# ESP32-C61 register map
Vendor: ESPRESSIF SYSTEMS (SHANGHAI) CO., LTD.; Series: ESP32 C-Series; File version: 1
CPU: RV32IMAC r0p0, little endian, no MPU, no FPU, 0 interrupt priority bits
Address unit: 32 bits
Registers are 32-bit, read-write, reset 0x0 unless marked. A register's access mark holds for its fields unless they carry their own. Offsets are from the block's base; [hi:lo] are bit positions; {n}, {i} and the like mark numbered series; 'fields as' and 'values as' point back to an identical list.

## SLC — SDIO SLC
Base 0x60017000
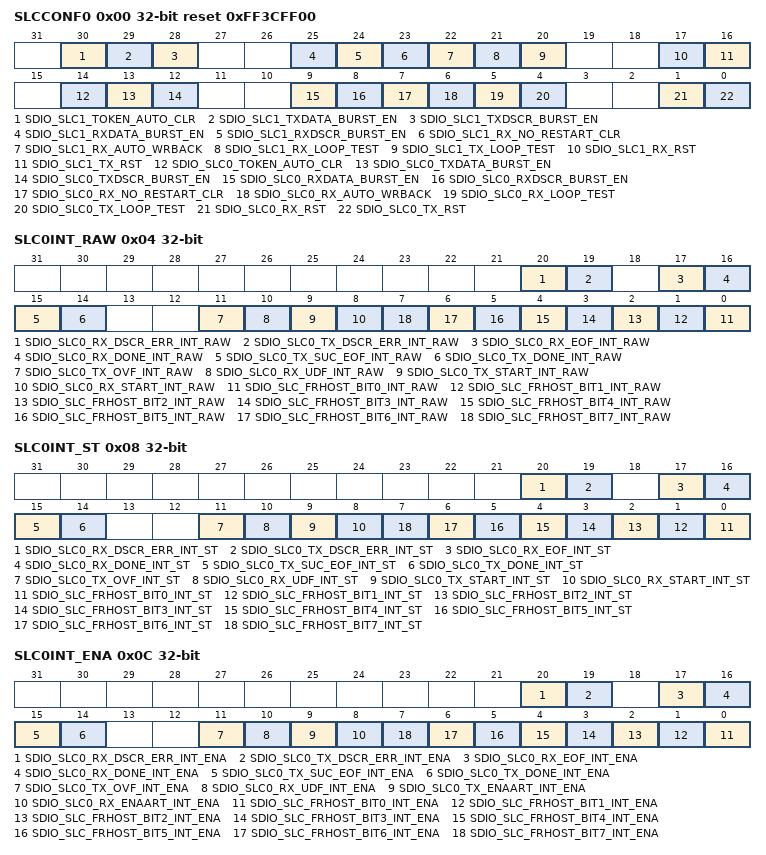
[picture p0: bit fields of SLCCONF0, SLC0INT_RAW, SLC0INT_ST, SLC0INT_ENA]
0x00 SLCCONF0 reset 0xFF3CFF00 — DMA configuration
  [30] SDIO_SLC1_TOKEN_AUTO_CLR — Please initialize to 0, and do not modify it.
  [29] SDIO_SLC1_TXDATA_BURST_EN — Configures whether SCL1 can use AHB burst operation when send data to memory.
  [28] SDIO_SLC1_TXDSCR_BURST_EN — Configures whether SCL1 can use AHB burst operation when read the TX linked list from memory.
  [25] SDIO_SLC1_RXDATA_BURST_EN — Configures whether SCL1 can use AHB burst operation when reading data from memory.
  [24] SDIO_SLC1_RXDSCR_BURST_EN — Configures whether SCL1 can use AHB burst operation when read the RX linked list from memory.
  [23] SDIO_SLC1_RX_NO_RESTART_CLR — Please initialize to 1, and do not modify it.
  [22] SDIO_SLC1_RX_AUTO_WRBACK — Configures whether SCL1 changes the owner bit of the RX linked list.
  [21] SDIO_SLC1_RX_LOOP_TEST — Configures whether SCL1 loops around when the slave buffer finishes sending packets to the host.
  [20] SDIO_SLC1_TX_LOOP_TEST — Configures whether SCL1 loops around when the slave buffer finishes receiving packets from the host.
  [17] SDIO_SLC1_RX_RST — Configures whether to reset RX FSM in SLC1.
  [16] SDIO_SLC1_TX_RST — Configures whether to reset TX FSM in SLC1.
  [14] SDIO_SLC0_TOKEN_AUTO_CLR — Please initialize to 0, and do not modify it.
  [13] SDIO_SLC0_TXDATA_BURST_EN — Configures whether SCL0 can use AHB burst operation when send data to memory.
  [12] SDIO_SLC0_TXDSCR_BURST_EN — Configures whether SCL0 can use AHB burst operation when read the TX linked list from memory.
  [9] SDIO_SLC0_RXDATA_BURST_EN — Configures whether SCL0 can use AHB burst operation when read data from memory.
  [8] SDIO_SLC0_RXDSCR_BURST_EN — Configures whether SCL0 can use AHB burst operation when reading the RX linked list from memory.
  [7] SDIO_SLC0_RX_NO_RESTART_CLR — Please initialize to 1, and do not modify it.
  [6] SDIO_SLC0_RX_AUTO_WRBACK — Configures whether SCL0 changes the owner bit of RX linked list.
  [5] SDIO_SLC0_RX_LOOP_TEST — Configures whether SCL0 loops around when the slave buffer finishes sending packets to the host.
  [4] SDIO_SLC0_TX_LOOP_TEST — Configures whether SCL0 loops around when the slave buffer finishes receiving packets from the host.
  [1] SDIO_SLC0_RX_RST — Configures whether to reset RX (slave to host) FSM in SCL0.
  [0] SDIO_SLC0_TX_RST — Configures whether to reset TX (host to slave) FSM (finite state machine) in SLC0.
0x04 SLC0INT_RAW — SLC0 to slave raw interrupt status
  [20] SDIO_SLC0_RX_DSCR_ERR_INT_RAW — The raw interrupt status of SLC0_RX_DSCR_ERR_INT.
  [19] SDIO_SLC0_TX_DSCR_ERR_INT_RAW — The raw interrupt status of SLC0_TX_DSCR_ERR_INT.
  [17] SDIO_SLC0_RX_EOF_INT_RAW — The raw interrupt status of SLC0_RX_EOF_INT.
  [16] SDIO_SLC0_RX_DONE_INT_RAW — The raw interrupt status of SLC0_RX_DONE_INT.
  [15] SDIO_SLC0_TX_SUC_EOF_INT_RAW — The raw interrupt status of SLC0_TX_SUC_EOF_INT.
  [14] SDIO_SLC0_TX_DONE_INT_RAW — The raw interrupt status of SLC0_TX_DONE_INT.
  [11] SDIO_SLC0_TX_OVF_INT_RAW — The raw interrupt status of SLC0_TX_OVF_INT.
  [10] SDIO_SLC0_RX_UDF_INT_RAW — The raw interrupt status of SLC0_RX_UDF_INT.
  [9] SDIO_SLC0_TX_START_INT_RAW — The raw interrupt status of SLC0_TX_START_INT.
  [8] SDIO_SLC0_RX_START_INT_RAW — The raw interrupt status of SLC0_RX_START_INT.
  [n] SDIO_SLC_FRHOST_BIT{n}_INT_RAW (n=0..7) — The raw interrupt status of SLC_FRHOST_BITn_INT (n: 0-7).
0x08 SLC0INT_ST ro — SLC0 to slave masked interrupt status
  [20] SDIO_SLC0_RX_DSCR_ERR_INT_ST — The masked interrupt status of SLC0_RX_DSCR_ERR_INT.
  [19] SDIO_SLC0_TX_DSCR_ERR_INT_ST — The masked interrupt status of SLC0_TX_DSCR_ERR_INT.
  [17] SDIO_SLC0_RX_EOF_INT_ST — The masked interrupt status of SLC0_RX_EOF_INT.
  [16] SDIO_SLC0_RX_DONE_INT_ST — The masked interrupt status of SLC0_RX_DONE_INT.
  [15] SDIO_SLC0_TX_SUC_EOF_INT_ST — The masked interrupt status of SLC0_TX_SUC_EOF_INT.
  [14] SDIO_SLC0_TX_DONE_INT_ST — The masked interrupt status of SLC0_TX_DONE_INT.
  [11] SDIO_SLC0_TX_OVF_INT_ST — The masked interrupt status of SLC0_TX_OVF_INT.
  [10] SDIO_SLC0_RX_UDF_INT_ST — The masked interrupt status of SLC0_RX_UDF_INT.
  [9] SDIO_SLC0_TX_START_INT_ST — The masked interrupt status of SLC0_TX_START_INT.
  [8] SDIO_SLC0_RX_START_INT_ST — The masked interrupt status of SLC0_RX_START_INT.
  [n] SDIO_SLC_FRHOST_BIT{n}_INT_ST (n=0..7) — The masked interrupt status of SLC_FRHOST_BITn_INT (n: 0-7).
0x0C SLC0INT_ENA — SLC0 to slave interrupt enable
  [20] SDIO_SLC0_RX_DSCR_ERR_INT_ENA — Write 1 to enable interrupt SLC0_RX_DSCR_ERR_INT.
  [19] SDIO_SLC0_TX_DSCR_ERR_INT_ENA — Write 1 to enable interrupt SLC0_TX_DSCR_ERR_INT.
  [17] SDIO_SLC0_RX_EOF_INT_ENA — Write 1 to enable interrupt SLC0_RX_EOF_INT.
  [16] SDIO_SLC0_RX_DONE_INT_ENA — Write 1 to enable interrupt SLC0_RX_DONE_INT.
  [15] SDIO_SLC0_TX_SUC_EOF_INT_ENA — Write 1 to enable interrupt SLC0_TX_SUC_EOF_INT.
  [14] SDIO_SLC0_TX_DONE_INT_ENA — Write 1 to enable interrupt SLC0_TX_DONE_INT.
  [11] SDIO_SLC0_TX_OVF_INT_ENA — Write 1 to enable interrupt SLC0_TX_OVF_INT.
  [10] SDIO_SLC0_RX_UDF_INT_ENA — Write 1 to enable interrupt SLC0_RX_UDF_INT.
  [9] SDIO_SLC0_TX_ENAART_INT_ENA — Write 1 to enable interrupt SLC0_TX_ENAART_INT.
  [8] SDIO_SLC0_RX_ENAART_INT_ENA — Write 1 to enable interrupt SLC0_RX_ENAART_INT.
  [n] SDIO_SLC_FRHOST_BIT{n}_INT_ENA (n=0..7) — Write 1 to enable interrupt SLC_FRHOST_BITn_INT (n: 0-7).
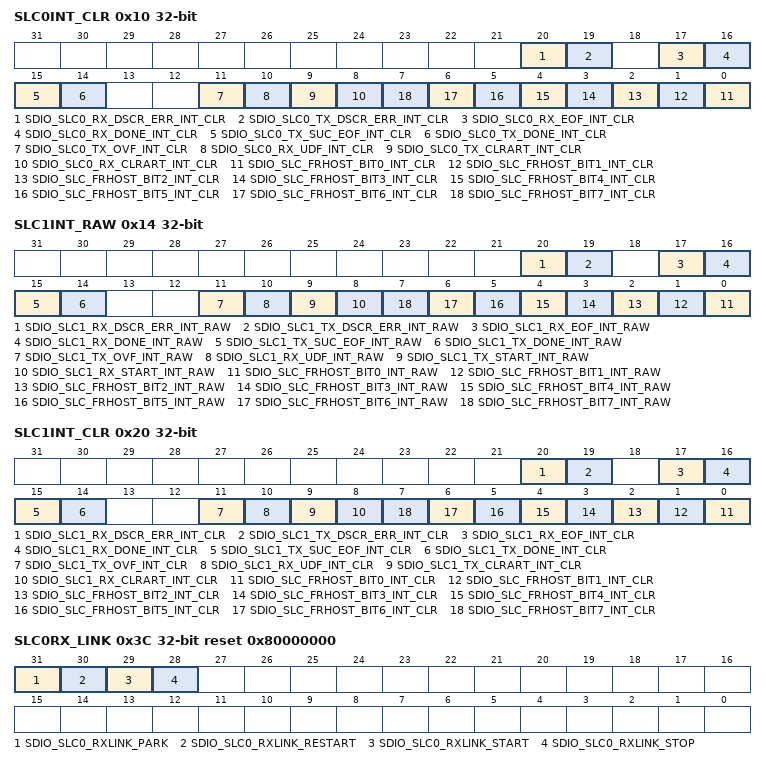
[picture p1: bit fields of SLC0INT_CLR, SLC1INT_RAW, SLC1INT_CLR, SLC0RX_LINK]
0x10 SLC0INT_CLR wo — SLC0 to slave interrupt clear
  [20] SDIO_SLC0_RX_DSCR_ERR_INT_CLR — Write 1 to clear interrupt SLC0_RX_DSCR_ERR_INT.
  [19] SDIO_SLC0_TX_DSCR_ERR_INT_CLR — Write 1 to clear interrupt SLC0_TX_DSCR_ERR_INT.
  [17] SDIO_SLC0_RX_EOF_INT_CLR — Write 1 to clear interrupt SLC0_RX_EOF_INT.
  [16] SDIO_SLC0_RX_DONE_INT_CLR — Write 1 to clear interrupt SLC0_RX_DONE_INT.
  [15] SDIO_SLC0_TX_SUC_EOF_INT_CLR — Write 1 to clear interrupt SLC0_TX_SUC_EOF_INT.
  [14] SDIO_SLC0_TX_DONE_INT_CLR — Write 1 to clear interrupt SLC0_TX_DONE_INT.
  [11] SDIO_SLC0_TX_OVF_INT_CLR — Write 1 to clear interrupt SLC0_TX_OVF_INT.
  [10] SDIO_SLC0_RX_UDF_INT_CLR — Write 1 to clear interrupt SLC0_RX_UDF_INT.
  [9] SDIO_SLC0_TX_CLRART_INT_CLR — Write 1 to clear interrupt SLC0_TX_CLRART_INT.
  [8] SDIO_SLC0_RX_CLRART_INT_CLR — Write 1 to clear interrupt SLC0_RX_CLRART_INT.
  [n] SDIO_SLC_FRHOST_BIT{n}_INT_CLR (n=0..7) — Write 1 to clear interrupt SLC_FRHOST_BITn_INT (n: 0-7).
0x14 SLC1INT_RAW — SLC1 to slave raw interrupt status
  [20] SDIO_SLC1_RX_DSCR_ERR_INT_RAW — The raw interrupt status of SLC1_RX_DSCR_ERR_INT.
  [19] SDIO_SLC1_TX_DSCR_ERR_INT_RAW — The raw interrupt status of SLC1_TX_DSCR_ERR_INT.
  [17] SDIO_SLC1_RX_EOF_INT_RAW — The raw interrupt status of SLC1_RX_EOF_INT.
  [16] SDIO_SLC1_RX_DONE_INT_RAW — The raw interrupt status of SLC1_RX_DONE_INT.
  [15] SDIO_SLC1_TX_SUC_EOF_INT_RAW — The raw interrupt status of SLC1_TX_SUC_EOF_INT.
  [14] SDIO_SLC1_TX_DONE_INT_RAW — The raw interrupt status of SLC1_TX_DONE_INT.
  [11] SDIO_SLC1_TX_OVF_INT_RAW — The raw interrupt status of SLC1_TX_OVF_INT.
  [10] SDIO_SLC1_RX_UDF_INT_RAW — The raw interrupt status of SLC1_RX_UDF_INT.
  [9] SDIO_SLC1_TX_START_INT_RAW — The raw interrupt status of SLC1_TX_START_INT.
  [8] SDIO_SLC1_RX_START_INT_RAW — The raw interrupt status of SLC1_RX_START_INT.
  [n] SDIO_SLC_FRHOST_BIT{n}_INT_RAW (n=0..7) — The raw interrupt status of SLC_FRHOST_BITn_INT (n: 0-7).
0x20 SLC1INT_CLR wo — SLC1 to slave interrupt clear
  [20] SDIO_SLC1_RX_DSCR_ERR_INT_CLR — Write 1 to clear interrupt SLC1_RX_DSCR_ERR_INT.
  [19] SDIO_SLC1_TX_DSCR_ERR_INT_CLR — Write 1 to clear interrupt SLC1_TX_DSCR_ERR_INT.
  [17] SDIO_SLC1_RX_EOF_INT_CLR — Write 1 to clear interrupt SLC1_RX_EOF_INT.
  [16] SDIO_SLC1_RX_DONE_INT_CLR — Write 1 to clear interrupt SLC1_RX_DONE_INT.
  [15] SDIO_SLC1_TX_SUC_EOF_INT_CLR — Write 1 to clear interrupt SLC1_TX_SUC_EOF_INT.
  [14] SDIO_SLC1_TX_DONE_INT_CLR — Write 1 to clear interrupt SLC1_TX_DONE_INT.
  [11] SDIO_SLC1_TX_OVF_INT_CLR — Write 1 to clear interrupt SLC1_TX_OVF_INT.
  [10] SDIO_SLC1_RX_UDF_INT_CLR — Write 1 to clear interrupt SLC1_RX_UDF_INT.
  [9] SDIO_SLC1_TX_CLRART_INT_CLR — Write 1 to clear interrupt SLC1_TX_CLRART_INT.
  [8] SDIO_SLC1_RX_CLRART_INT_CLR — Write 1 to clear interrupt SLC1_RX_CLRART_INT.
  [n] SDIO_SLC_FRHOST_BIT{n}_INT_CLR (n=0..7) — Write 1 to clear interrupt SLC_FRHOST_BITn_INT (n: 0-7).
0x3C SLC0RX_LINK reset 0x80000000 — SLC0 RX linked list configuration
  [31] SDIO_SLC0_RXLINK_PARK — Represents SLC0 RX linked list FSM state.
  [30] SDIO_SLC0_RXLINK_RESTART — Configures whether to restart and continue SLC0 RX linked list operation.
  [29] SDIO_SLC0_RXLINK_START — Configures whether to start SLC0 RX linked list operation from the address indicated by SDIO_SLC0_RXLINK_ADDR.
  [28] SDIO_SLC0_RXLINK_STOP — Configures whether to stop SLC0 RX linked list operation.
0x40 SLC0RX_LINK_ADDR — SLC0 RX linked list address
  [31:0] SDIO_SLC0_RXLINK_ADDR — Configures SLC0 RX linked list initial address.
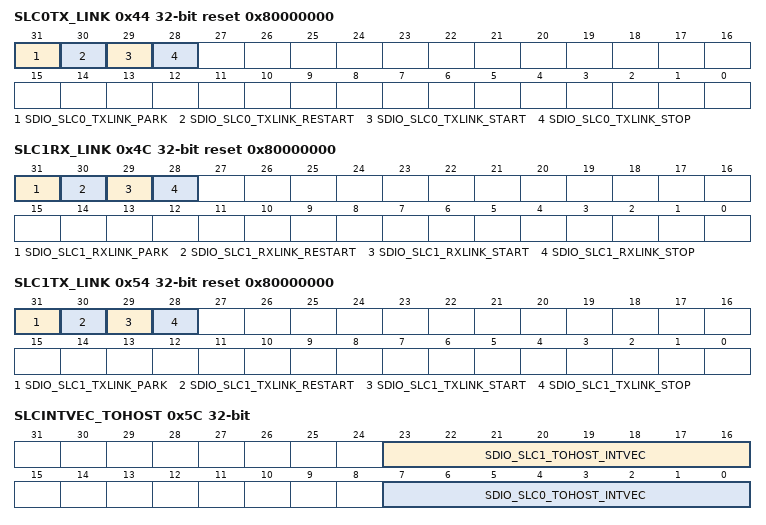
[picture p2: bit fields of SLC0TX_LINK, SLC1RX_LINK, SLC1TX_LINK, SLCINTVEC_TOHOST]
0x44 SLC0TX_LINK reset 0x80000000 — SLC0 TX linked list configuration
  [31] SDIO_SLC0_TXLINK_PARK — Represents SLC0 TX linked list FSM state.
  [30] SDIO_SLC0_TXLINK_RESTART — Configures whether to restart and continue SLC0 TX linked list operation.
  [29] SDIO_SLC0_TXLINK_START — Configures whether to start SLC0 TX linked list operation from the address indicated by SDIO_SLC0_TXLINK_ADDR.
  [28] SDIO_SLC0_TXLINK_STOP — Configures whether to stop SLC0 TX linked list operation.
0x48 SLC0TX_LINK_ADDR — SLC0 TX linked list address
  [31:0] SDIO_SLC0_TXLINK_ADDR — Configures SLC0 TX linked list initial address.
0x4C SLC1RX_LINK reset 0x80000000 — SLC1 RX linked list configuration
  [31] SDIO_SLC1_RXLINK_PARK — Represents SLC1 RX linked list FSM state.
  [30] SDIO_SLC1_RXLINK_RESTART — Configures whether to restart and continue SLC1 RX linked list operation.
  [29] SDIO_SLC1_RXLINK_START — Configures whether to start SLC1 RX linked list operation from the address indicated by SDIO_SLC1_RXLINK_ADDR.
  [28] SDIO_SLC1_RXLINK_STOP — Configures whether to stop SLC1 RX linked list operation.
0x50 SLC1RX_LINK_ADDR — SLC1 RX linked list address
  [31:0] SDIO_SLC1_RXLINK_ADDR — Configures SLC1 RX linked list initial address.
0x54 SLC1TX_LINK reset 0x80000000 — SLC1 TX linked list configuration
  [31] SDIO_SLC1_TXLINK_PARK — Represents SLC1 TX linked list FSM state.
  [30] SDIO_SLC1_TXLINK_RESTART — Configures whether to restart and continue SLC1 TX linked list operation.
  [29] SDIO_SLC1_TXLINK_START — Configures whether to start SLC1 TX linked list operation from the address indicated by SDIO_SLC1_TXLINK_ADDR.
  [28] SDIO_SLC1_TXLINK_STOP — Configures whether to stop SLC1 TX linked list operation.
0x58 SLC1TX_LINK_ADDR — SLC1 TX linked list address
  [31:0] SDIO_SLC1_TXLINK_ADDR — Configures SLC1 TX linked list initial address.
0x5C SLCINTVEC_TOHOST wo — Slave to host interrupt vector set
  [23:16] SDIO_SLC1_TOHOST_INTVEC — The interrupt set bit of SLCHOST_SLC1_TOHOST_BITn_INT (n: 0-7).
  [7:0] SDIO_SLC0_TOHOST_INTVEC — The interrupt set bit of SLCHOST_SLC0_TOHOST_BITn_INT (n: 0-7).
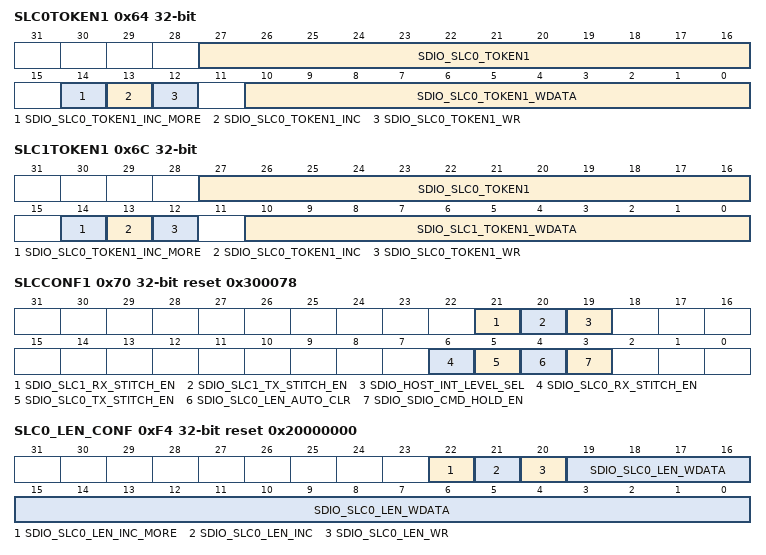
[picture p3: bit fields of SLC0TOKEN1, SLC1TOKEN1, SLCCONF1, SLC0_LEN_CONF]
0x64 SLC0TOKEN1 — SLC0 receiving buffer configuration
  [27:16] SDIO_SLC0_TOKEN1 ro — Represents the SLC0 accumulated number of buffers for receiving packets.
  [14] SDIO_SLC0_TOKEN1_INC_MORE wo — Configures this bit to 1 to add the value of SDIO_SLC0_TOKEN1_WDATA to SDIO_SLC0_TOKEN1.
  [13] SDIO_SLC0_TOKEN1_INC wo — Configures this bit to 1 to add 1 to SDIO_SLC0_TOKEN1.
  [12] SDIO_SLC0_TOKEN1_WR wo — Configures this bit to 1 to write SDIO_SLC0_TOKEN1_WDATA into SDIO_SLC0_TOKEN1.
  [10:0] SDIO_SLC0_TOKEN1_WDATA wo — Configures SLC0 token 1 value.
0x6C SLC1TOKEN1 — SLC1 receiving buffer configuration
  [27:16] SDIO_SLC0_TOKEN1 ro — Represents the SLC1 accumulated number of buffers for receiving packets.
  [14] SDIO_SLC0_TOKEN1_INC_MORE wo — Configures this bit to 1 to add the value of SDIO_SLC1_TOKEN1_WDATA to SDIO_SLC1_TOKEN1.
  [13] SDIO_SLC0_TOKEN1_INC wo — Configures this bit to 1 to add 1 to SDIO_SLC1_TOKEN1.
  [12] SDIO_SLC0_TOKEN1_WR wo — Configures this bit to 1 to write SDIO_SLC1_TOKEN1_WDATA into SDIO_SLC1_TOKEN1.
  [10:0] SDIO_SLC1_TOKEN1_WDATA wo — Configures SLC1 token1 value.
0x70 SLCCONF1 reset 0x300078 — DMA configuration
  [21] SDIO_SLC1_RX_STITCH_EN — Please initialize to 0, and do not modify it.
  [20] SDIO_SLC1_TX_STITCH_EN — Please initialize to 0, and do not modify it.
  [19] SDIO_HOST_INT_LEVEL_SEL — Configures the polarity of interrupt to host.
  [6] SDIO_SLC0_RX_STITCH_EN — Please initialize to 0, and do not modify it.
  [5] SDIO_SLC0_TX_STITCH_EN — Please initialize to 0, and do not modify it.
  [4] SDIO_SLC0_LEN_AUTO_CLR — Please initialize to 0, and do not modify it.
  [3] SDIO_SDIO_CMD_HOLD_EN — Please initialize to 0, and do not modify it.
0xA8 SLC_RX_DSCR_CONF reset 0x203701A — DMA slave to host configuration register
  [1] SDIO_SLC0_TOKEN_NO_REPLACE — Please initialize to 1, and do not modify it.
0xF4 SLC0_LEN_CONF wo reset 0x20000000 — Length control of transmitting packets
  [22] SDIO_SLC0_LEN_INC_MORE — Configures this bit to 1 to add the value of SDIO_SLC0_LEN_WDATA to SDIO_SLC0_LEN and SLCHOST_HOSTSLCHOST_SLC0_LEN.
  [21] SDIO_SLC0_LEN_INC — Configures this bit to 1 to add 1 to SDIO_SLC0_LEN and SLCHOST_HOSTSLCHOST_SLC0_LEN.
  [20] SDIO_SLC0_LEN_WR — Configures this bit to 1 to write SDIO_SLC0_LEN_WDATA into SDIO_SLC0_LEN and SLCHOST_HOSTSLCHOST_SLC0_LEN.
  [19:0] SDIO_SLC0_LEN_WDATA — Configures the length of the data that the slave wants to send.
0xF8 SLC0_LENGTH ro — Length of transmitting packets
  [19:0] SDIO_SLC0_LEN — Represents the accumulated length of data that the slave wants to send.
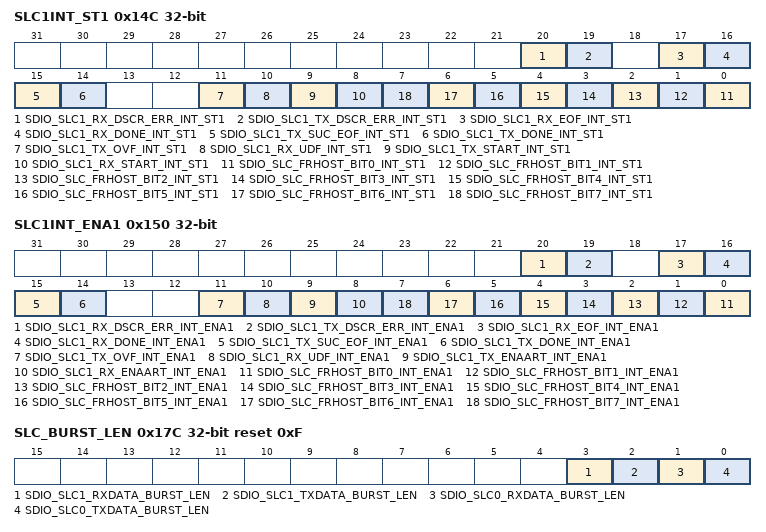
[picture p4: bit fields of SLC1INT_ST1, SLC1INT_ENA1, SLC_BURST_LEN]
0x14C SLC1INT_ST1 ro — SLC1 to slave masked interrupt status
  [20] SDIO_SLC1_RX_DSCR_ERR_INT_ST1 — The masked interrupt status of SLC1_RX_DSCR_ERR_INT.
  [19] SDIO_SLC1_TX_DSCR_ERR_INT_ST1 — The masked interrupt status of SLC1_TX_DSCR_ERR_INT.
  [17] SDIO_SLC1_RX_EOF_INT_ST1 — The masked interrupt status of SLC1_RX_EOF_INT.
  [16] SDIO_SLC1_RX_DONE_INT_ST1 — The masked interrupt status of SLC1_RX_DONE_INT.
  [15] SDIO_SLC1_TX_SUC_EOF_INT_ST1 — The masked interrupt status of SLC1_TX_SUC_EOF_INT.
  [14] SDIO_SLC1_TX_DONE_INT_ST1 — The masked interrupt status of SLC1_TX_DONE_INT.
  [11] SDIO_SLC1_TX_OVF_INT_ST1 — The masked interrupt status of SLC1_TX_OVF_INT.
  [10] SDIO_SLC1_RX_UDF_INT_ST1 — The masked interrupt status of SLC1_RX_UDF_INT.
  [9] SDIO_SLC1_TX_START_INT_ST1 — The masked interrupt status of SLC1_TX_START_INT.
  [8] SDIO_SLC1_RX_START_INT_ST1 — The masked interrupt status of SLC1_RX_START_INT.
  [n] SDIO_SLC_FRHOST_BIT{n}_INT_ST1 (n=0..7) — The masked interrupt status of SLC_FRHOST_BITn_INT (n: 0-7).
0x150 SLC1INT_ENA1 — SLC1 to slave interrupt enable
  [20] SDIO_SLC1_RX_DSCR_ERR_INT_ENA1 — Write 1 to enable interrupt SLC1_RX_DSCR_ERR_INT.
  [19] SDIO_SLC1_TX_DSCR_ERR_INT_ENA1 — Write 1 to enable interrupt SLC1_TX_DSCR_ERR_INT.
  [17] SDIO_SLC1_RX_EOF_INT_ENA1 — Write 1 to enable interrupt SLC1_RX_EOF_INT.
  [16] SDIO_SLC1_RX_DONE_INT_ENA1 — Write 1 to enable interrupt SLC1_RX_DONE_INT.
  [15] SDIO_SLC1_TX_SUC_EOF_INT_ENA1 — Write 1 to enable interrupt SLC1_TX_SUC_EOF_INT.
  [14] SDIO_SLC1_TX_DONE_INT_ENA1 — Write 1 to enable interrupt SLC1_TX_DONE_INT.
  [11] SDIO_SLC1_TX_OVF_INT_ENA1 — Write 1 to enable interrupt SLC1_TX_OVF_INT.
  [10] SDIO_SLC1_RX_UDF_INT_ENA1 — Write 1 to enable interrupt SLC1_RX_UDF_INT.
  [9] SDIO_SLC1_TX_ENAART_INT_ENA1 — Write 1 to enable interrupt SLC1_TX_ENAART_INT.
  [8] SDIO_SLC1_RX_ENAART_INT_ENA1 — Write 1 to enable interrupt SLC1_RX_ENAART_INT.
  [n] SDIO_SLC_FRHOST_BIT{n}_INT_ENA1 (n=0..7) — Write 1 to enable interrupt SLC_FRHOST_BITn_INT (n: 0-7).
0x154 SLC0_TX_SHAREMEM_START — SLC0 AHB TX start address range
  [31:0] SDIO_SDIO_SLC0_TX_SHAREMEM_START_ADDR — Configures SLC0 host to slave channel AHB start address boundary.
0x158 SLC0_TX_SHAREMEM_END reset 0xFFFFFFFF — SLC0 AHB TX end address range
  [31:0] SDIO_SDIO_SLC0_TX_SHAREMEM_END_ADDR — Configures SLC0 host to slave channel AHB end address boundary.
0x15C SLC0_RX_SHAREMEM_START — SLC0 AHB RX start address range
  [31:0] SDIO_SDIO_SLC0_RX_SHAREMEM_START_ADDR — Configures SLC0 slave to host channel AHB start address boundary.
0x160 SLC0_RX_SHAREMEM_END reset 0xFFFFFFFF — SLC0 AHB RX end address range
  [31:0] SDIO_SDIO_SLC0_RX_SHAREMEM_END_ADDR — Configures SLC0 slave to host channel AHB end address boundary.
0x164 SLC1_TX_SHAREMEM_START — SLC1 AHB TX start address range
  fields as SLC0_RX_SHAREMEM_START
0x168 SLC1_TX_SHAREMEM_END reset 0xFFFFFFFF — SLC1 AHB TX end address range
  [31:0] SDIO_SDIO_SLC1_TX_SHAREMEM_END_ADDR — Configures SLC1 host to slave channel AHB end address boundary.
0x16C SLC1_RX_SHAREMEM_START — SLC1 AHB RX start address range
  [31:0] SDIO_SDIO_SLC1_RX_SHAREMEM_START_ADDR — Configures SLC1 slave to host channel AHB start address boundary.
0x170 SLC1_RX_SHAREMEM_END reset 0xFFFFFFFF — SLC1 AHB RX end address range
  [31:0] SDIO_SDIO_SLC1_RX_SHAREMEM_END_ADDR — Configures SLC1 slave to host channel AHB end address boundary.
0x17C SLC_BURST_LEN reset 0xF — DMA AHB burst type configuration
  [3] SDIO_SLC1_RXDATA_BURST_LEN — Configures SLC1 slave to host channel AHB burst type.
  [2] SDIO_SLC1_TXDATA_BURST_LEN — Configures SLC1 host to slave channel AHB burst type.
  [1] SDIO_SLC0_RXDATA_BURST_LEN — Configures SLC0 slave to host channel AHB burst type.
  [0] SDIO_SLC0_TXDATA_BURST_LEN — Configures SLC0 host to slave channel AHB burst type.
